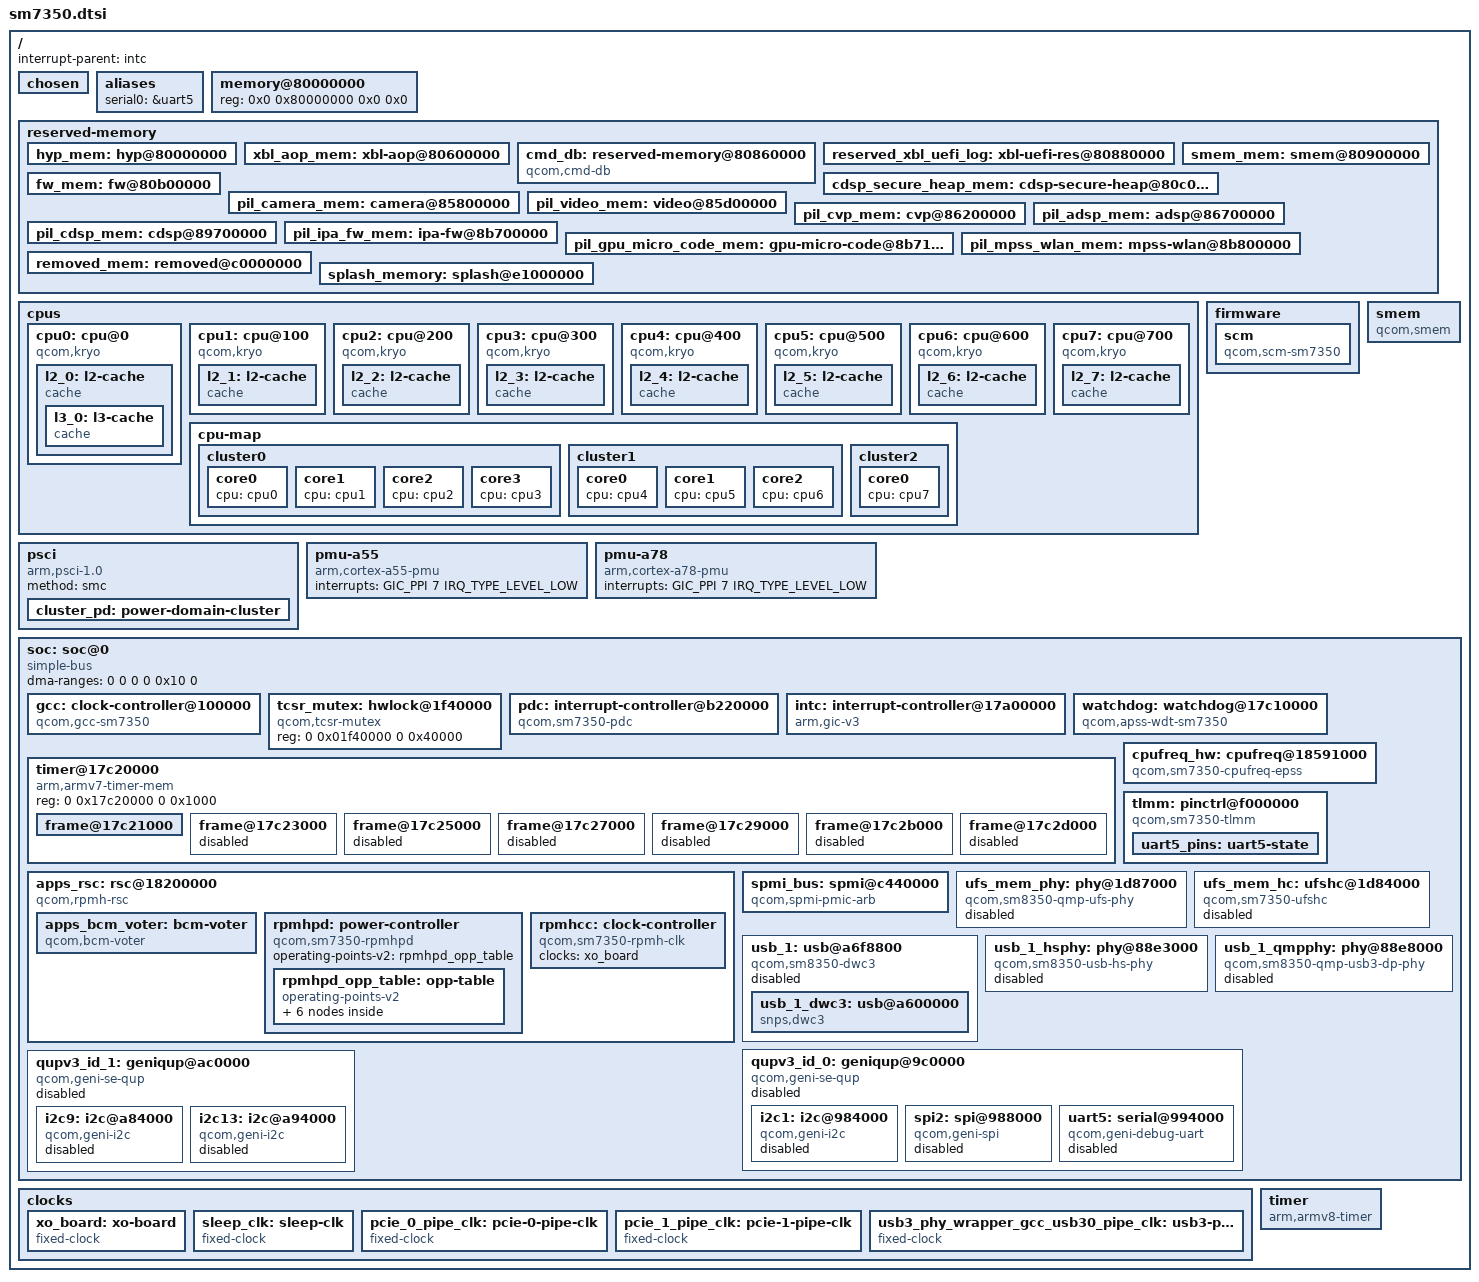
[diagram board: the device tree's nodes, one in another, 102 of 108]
// SPDX-License-Identifier: BSD-3-Clause
/*
 * Qualcomm SM7350 (Shima) SoC device tree
 *
 * Based on the downstream shima.dtsi and the mainline SM7325/Kodiak support.
 * Copyright (c) 2020-2021, The Linux Foundation. All rights reserved.
 * Copyright (c) 2026, Claude Agent <claude-agent@localhost>
 */

#include <dt-bindings/clock/qcom,gcc-sm7350.h>
#include <dt-bindings/clock/qcom,rpmh.h>
#include <dt-bindings/gpio/gpio.h>
#include <dt-bindings/interrupt-controller/arm-gic.h>
#include <dt-bindings/interrupt-controller/irq.h>
#include <dt-bindings/phy/phy-qcom-qmp.h>
#include <dt-bindings/power/qcom,rpmhpd.h>
#include <dt-bindings/soc/qcom,rpmh-rsc.h>
#include <dt-bindings/spmi/spmi.h>

/ {
	interrupt-parent = <&intc>;
	#address-cells = <2>;
	#size-cells = <2>;

	chosen { };

	aliases {
		serial0 = &uart5;
	};

	memory@80000000 {
		device_type = "memory";
		/* We expect the bootloader to fill in the size */
		reg = <0x0 0x80000000 0x0 0x0>;
	};

	reserved-memory {
		#address-cells = <2>;
		#size-cells = <2>;
		ranges;

		hyp_mem: hyp@80000000 {
			reg = <0x0 0x80000000 0x0 0x600000>;
			no-map;
		};

		xbl_aop_mem: xbl-aop@80600000 {
			reg = <0x0 0x80600000 0x0 0x260000>;
			no-map;
		};

		cmd_db: reserved-memory@80860000 {
			compatible = "qcom,cmd-db";
			reg = <0x0 0x80860000 0x0 0x20000>;
			no-map;
		};

		reserved_xbl_uefi_log: xbl-uefi-res@80880000 {
			reg = <0x0 0x80880000 0x0 0x14000>;
			no-map;
		};

		smem_mem: smem@80900000 {
			reg = <0x0 0x80900000 0x0 0x200000>;
			no-map;
		};

		fw_mem: fw@80b00000 {
			reg = <0x0 0x80b00000 0x0 0x100000>;
			no-map;
		};

		cdsp_secure_heap_mem: cdsp-secure-heap@80c00000 {
			reg = <0x0 0x80c00000 0x0 0x4600000>;
			no-map;
		};

		pil_camera_mem: camera@85800000 {
			reg = <0x0 0x85800000 0x0 0x500000>;
			no-map;
		};

		pil_video_mem: video@85d00000 {
			reg = <0x0 0x85d00000 0x0 0x500000>;
			no-map;
		};

		pil_cvp_mem: cvp@86200000 {
			reg = <0x0 0x86200000 0x0 0x500000>;
			no-map;
		};

		pil_adsp_mem: adsp@86700000 {
			reg = <0x0 0x86700000 0x0 0x3000000>;
			no-map;
		};

		pil_cdsp_mem: cdsp@89700000 {
			reg = <0x0 0x89700000 0x0 0x1e00000>;
			no-map;
		};

		pil_ipa_fw_mem: ipa-fw@8b700000 {
			reg = <0x0 0x8b700000 0x0 0x10000>;
			no-map;
		};

		pil_gpu_micro_code_mem: gpu-micro-code@8b71a000 {
			reg = <0x0 0x8b71a000 0x0 0x2000>;
			no-map;
		};

		pil_mpss_wlan_mem: mpss-wlan@8b800000 {
			reg = <0x0 0x8b800000 0x0 0x10000000>;
			no-map;
		};

		removed_mem: removed@c0000000 {
			reg = <0x0 0xc0000000 0x0 0x5100000>;
			no-map;
		};

		splash_memory: splash@e1000000 {
			reg = <0x0 0xe1000000 0x0 0x2300000>;
			no-map;
		};
	};

	cpus {
		#address-cells = <2>;
		#size-cells = <0>;

		cpu0: cpu@0 {
			device_type = "cpu";
			compatible = "qcom,kryo";
			reg = <0x0 0x0>;
			clocks = <&cpufreq_hw 0>;
			enable-method = "psci";
			next-level-cache = <&l2_0>;
			qcom,freq-domain = <&cpufreq_hw 0>;
			capacity-dmips-mhz = <1024>;
			dynamic-power-coefficient = <100>;
			#cooling-cells = <2>;

			l2_0: l2-cache {
				compatible = "cache";
				cache-level = <2>;
				cache-unified;
				next-level-cache = <&l3_0>;
				l3_0: l3-cache {
					compatible = "cache";
					cache-level = <3>;
					cache-unified;
				};
			};
		};

		cpu1: cpu@100 {
			device_type = "cpu";
			compatible = "qcom,kryo";
			reg = <0x0 0x100>;
			clocks = <&cpufreq_hw 0>;
			enable-method = "psci";
			next-level-cache = <&l2_1>;
			qcom,freq-domain = <&cpufreq_hw 0>;
			capacity-dmips-mhz = <1024>;
			dynamic-power-coefficient = <100>;
			#cooling-cells = <2>;

			l2_1: l2-cache {
				compatible = "cache";
				cache-level = <2>;
				cache-unified;
				next-level-cache = <&l3_0>;
			};
		};

		cpu2: cpu@200 {
			device_type = "cpu";
			compatible = "qcom,kryo";
			reg = <0x0 0x200>;
			clocks = <&cpufreq_hw 0>;
			enable-method = "psci";
			next-level-cache = <&l2_2>;
			qcom,freq-domain = <&cpufreq_hw 0>;
			capacity-dmips-mhz = <1024>;
			dynamic-power-coefficient = <100>;
			#cooling-cells = <2>;

			l2_2: l2-cache {
				compatible = "cache";
				cache-level = <2>;
				cache-unified;
				next-level-cache = <&l3_0>;
			};
		};

		cpu3: cpu@300 {
			device_type = "cpu";
			compatible = "qcom,kryo";
			reg = <0x0 0x300>;
			clocks = <&cpufreq_hw 0>;
			enable-method = "psci";
			next-level-cache = <&l2_3>;
			qcom,freq-domain = <&cpufreq_hw 0>;
			capacity-dmips-mhz = <1024>;
			dynamic-power-coefficient = <100>;
			#cooling-cells = <2>;

			l2_3: l2-cache {
				compatible = "cache";
				cache-level = <2>;
				cache-unified;
				next-level-cache = <&l3_0>;
			};
		};

		cpu4: cpu@400 {
			device_type = "cpu";
			compatible = "qcom,kryo";
			reg = <0x0 0x400>;
			clocks = <&cpufreq_hw 1>;
			enable-method = "psci";
			next-level-cache = <&l2_4>;
			qcom,freq-domain = <&cpufreq_hw 1>;
			capacity-dmips-mhz = <1946>;
			dynamic-power-coefficient = <520>;
			#cooling-cells = <2>;

			l2_4: l2-cache {
				compatible = "cache";
				cache-level = <2>;
				cache-unified;
				next-level-cache = <&l3_0>;
			};
		};

		cpu5: cpu@500 {
			device_type = "cpu";
			compatible = "qcom,kryo";
			reg = <0x0 0x500>;
			clocks = <&cpufreq_hw 1>;
			enable-method = "psci";
			next-level-cache = <&l2_5>;
			qcom,freq-domain = <&cpufreq_hw 1>;
			capacity-dmips-mhz = <1946>;
			dynamic-power-coefficient = <520>;
			#cooling-cells = <2>;

			l2_5: l2-cache {
				compatible = "cache";
				cache-level = <2>;
				cache-unified;
				next-level-cache = <&l3_0>;
			};
		};

		cpu6: cpu@600 {
			device_type = "cpu";
			compatible = "qcom,kryo";
			reg = <0x0 0x600>;
			clocks = <&cpufreq_hw 1>;
			enable-method = "psci";
			next-level-cache = <&l2_6>;
			qcom,freq-domain = <&cpufreq_hw 1>;
			capacity-dmips-mhz = <1946>;
			dynamic-power-coefficient = <520>;
			#cooling-cells = <2>;

			l2_6: l2-cache {
				compatible = "cache";
				cache-level = <2>;
				cache-unified;
				next-level-cache = <&l3_0>;
			};
		};

		cpu7: cpu@700 {
			device_type = "cpu";
			compatible = "qcom,kryo";
			reg = <0x0 0x700>;
			clocks = <&cpufreq_hw 2>;
			enable-method = "psci";
			next-level-cache = <&l2_7>;
			qcom,freq-domain = <&cpufreq_hw 2>;
			capacity-dmips-mhz = <1985>;
			dynamic-power-coefficient = <552>;
			#cooling-cells = <2>;

			l2_7: l2-cache {
				compatible = "cache";
				cache-level = <2>;
				cache-unified;
				next-level-cache = <&l3_0>;
			};
		};

		cpu-map {
			cluster0 {
				core0 { cpu = <&cpu0>; };
				core1 { cpu = <&cpu1>; };
				core2 { cpu = <&cpu2>; };
				core3 { cpu = <&cpu3>; };
			};

			cluster1 {
				core0 { cpu = <&cpu4>; };
				core1 { cpu = <&cpu5>; };
				core2 { cpu = <&cpu6>; };
			};

			cluster2 {
				core0 { cpu = <&cpu7>; };
			};
		};
	};

	psci {
		compatible = "arm,psci-1.0";
		method = "smc";

		cluster_pd: power-domain-cluster {
			#power-domain-cells = <0>;
		};
	};

	firmware {
		scm: scm {
			compatible = "qcom,scm-sm7350", "qcom,scm";
			#reset-cells = <1>;
		};
	};

	pmu-a55 {
		compatible = "arm,cortex-a55-pmu";
		interrupts = <GIC_PPI 7 IRQ_TYPE_LEVEL_LOW>;
	};

	pmu-a78 {
		compatible = "arm,cortex-a78-pmu";
		interrupts = <GIC_PPI 7 IRQ_TYPE_LEVEL_LOW>;
	};

	smem: smem {
		compatible = "qcom,smem";
		memory-region = <&smem_mem>;
		hwlocks = <&tcsr_mutex 3>;
	};

	soc: soc@0 {
		#address-cells = <2>;
		#size-cells = <2>;
		ranges = <0 0 0 0 0x10 0>;
		dma-ranges = <0 0 0 0 0x10 0>;
		compatible = "simple-bus";

		gcc: clock-controller@100000 {
			compatible = "qcom,gcc-sm7350";
			reg = <0 0x00100000 0 0x1f0000>;
			#clock-cells = <1>;
			#reset-cells = <1>;
			#power-domain-cells = <1>;

			clocks = <&rpmhcc RPMH_CXO_CLK>,
				 <&sleep_clk>,
				 <&pcie_0_pipe_clk>, <&pcie_1_pipe_clk>,
				 <&ufs_mem_phy 0>, <&ufs_mem_phy 1>, <&ufs_mem_phy 2>,
				 <&usb3_phy_wrapper_gcc_usb30_pipe_clk>;
			clock-names = "bi_tcxo", "sleep_clk",
				      "pcie_0_pipe_clk", "pcie_1_pipe_clk",
				      "ufs_phy_rx_symbol_0_clk", "ufs_phy_rx_symbol_1_clk",
				      "ufs_phy_tx_symbol_0_clk",
				      "usb3_phy_wrapper_gcc_usb30_pipe_clk";

			power-domains = <&rpmhpd SM7350_CX>;
		};

		tcsr_mutex: hwlock@1f40000 {
			compatible = "qcom,tcsr-mutex";
			reg = <0 0x01f40000 0 0x40000>;
			#hwlock-cells = <1>;
		};

		pdc: interrupt-controller@b220000 {
			compatible = "qcom,sm7350-pdc", "qcom,pdc";
			reg = <0 0x0b220000 0 0x30000>,
			      <0 0x17c000f0 0 0x64>;
			qcom,pdc-ranges = <0 480 40>, <40 140 14>, <54 263 1>,
					  <55 306 4>, <59 312 3>, <62 374 2>,
					  <64 434 2>, <66 438 3>, <69 86 1>,
					  <70 520 54>, <124 609 31>, <155 63 1>,
					  <156 716 12>;
			#interrupt-cells = <2>;
			interrupt-parent = <&intc>;
			interrupt-controller;
		};

		intc: interrupt-controller@17a00000 {
			compatible = "arm,gic-v3";
			reg = <0 0x17a00000 0 0x10000>,	/* GICD */
			      <0 0x17a60000 0 0x100000>;	/* GICR * 8 */
			interrupts = <GIC_PPI 9 IRQ_TYPE_LEVEL_LOW>;
			#interrupt-cells = <3>;
			interrupt-controller;
		};

		watchdog: watchdog@17c10000 {
			compatible = "qcom,apss-wdt-sm7350", "qcom,kpss-wdt";
			reg = <0 0x17c10000 0 0x1000>;
			clocks = <&sleep_clk>;
			interrupts = <GIC_SPI 0 IRQ_TYPE_EDGE_RISING>;
		};

		timer@17c20000 {
			#address-cells = <1>;
			#size-cells = <1>;
			ranges = <0 0 0 0x20000000>;
			compatible = "arm,armv7-timer-mem";
			reg = <0 0x17c20000 0 0x1000>;

			frame@17c21000 {
				frame-number = <0>;
				interrupts = <GIC_SPI 8 IRQ_TYPE_LEVEL_HIGH>,
					     <GIC_SPI 6 IRQ_TYPE_LEVEL_HIGH>;
				reg = <0x17c21000 0x1000>,
				      <0x17c22000 0x1000>;
			};

			frame@17c23000 {
				frame-number = <1>;
				interrupts = <GIC_SPI 9 IRQ_TYPE_LEVEL_HIGH>;
				reg = <0x17c23000 0x1000>;
				status = "disabled";
			};

			frame@17c25000 {
				frame-number = <2>;
				interrupts = <GIC_SPI 10 IRQ_TYPE_LEVEL_HIGH>;
				reg = <0x17c25000 0x1000>;
				status = "disabled";
			};

			frame@17c27000 {
				frame-number = <3>;
				interrupts = <GIC_SPI 11 IRQ_TYPE_LEVEL_HIGH>;
				reg = <0x17c27000 0x1000>;
				status = "disabled";
			};

			frame@17c29000 {
				frame-number = <4>;
				interrupts = <GIC_SPI 12 IRQ_TYPE_LEVEL_HIGH>;
				reg = <0x17c29000 0x1000>;
				status = "disabled";
			};

			frame@17c2b000 {
				frame-number = <5>;
				interrupts = <GIC_SPI 13 IRQ_TYPE_LEVEL_HIGH>;
				reg = <0x17c2b000 0x1000>;
				status = "disabled";
			};

			frame@17c2d000 {
				frame-number = <6>;
				interrupts = <GIC_SPI 14 IRQ_TYPE_LEVEL_HIGH>;
				reg = <0x17c2d000 0x1000>;
				status = "disabled";
			};
		};

		apps_rsc: rsc@18200000 {
			compatible = "qcom,rpmh-rsc";
			reg = <0 0x18200000 0 0x10000>,
			      <0 0x18210000 0 0x10000>,
			      <0 0x18220000 0 0x10000>;
			reg-names = "drv-0", "drv-1", "drv-2";
			interrupts = <GIC_SPI 3 IRQ_TYPE_LEVEL_HIGH>,
				     <GIC_SPI 4 IRQ_TYPE_LEVEL_HIGH>,
				     <GIC_SPI 5 IRQ_TYPE_LEVEL_HIGH>;
			power-domains = <&cluster_pd>;
			qcom,tcs-offset = <0xd00>;
			qcom,drv-id = <2>;
			qcom,tcs-config = <ACTIVE_TCS 2>,
					  <SLEEP_TCS 3>,
					  <WAKE_TCS 3>,
					  <CONTROL_TCS 0>;

			apps_bcm_voter: bcm-voter {
				compatible = "qcom,bcm-voter";
			};

			rpmhpd: power-controller {
				compatible = "qcom,sm7350-rpmhpd";
				#power-domain-cells = <1>;
				operating-points-v2 = <&rpmhpd_opp_table>;

				rpmhpd_opp_table: opp-table {
					compatible = "operating-points-v2";

					rpmhpd_opp_ret: opp1 {
						opp-level = <RPMH_REGULATOR_LEVEL_RETENTION>;
					};

					rpmhpd_opp_low_svs: opp2 {
						opp-level = <RPMH_REGULATOR_LEVEL_LOW_SVS>;
					};

					rpmhpd_opp_svs: opp3 {
						opp-level = <RPMH_REGULATOR_LEVEL_SVS>;
					};

					rpmhpd_opp_svs_l1: opp4 {
						opp-level = <RPMH_REGULATOR_LEVEL_SVS_L1>;
					};

					rpmhpd_opp_nom: opp5 {
						opp-level = <RPMH_REGULATOR_LEVEL_NOM>;
					};

					rpmhpd_opp_turbo: opp6 {
						opp-level = <RPMH_REGULATOR_LEVEL_TURBO>;
					};
				};
			};

			rpmhcc: clock-controller {
				compatible = "qcom,sm7350-rpmh-clk";
				clocks = <&xo_board>;
				clock-names = "xo";
				#clock-cells = <1>;
			};
		};

		cpufreq_hw: cpufreq@18591000 {
			compatible = "qcom,sm7350-cpufreq-epss", "qcom,cpufreq-epss";
			reg = <0 0x18591000 0 0x1000>,
			      <0 0x18592000 0 0x1000>,
			      <0 0x18593000 0 0x1000>;
			interrupts = <GIC_SPI 30 IRQ_TYPE_LEVEL_HIGH>,
				     <GIC_SPI 31 IRQ_TYPE_LEVEL_HIGH>,
				     <GIC_SPI 19 IRQ_TYPE_LEVEL_HIGH>;
			interrupt-names = "dcvsh-irq-0", "dcvsh-irq-1", "dcvsh-irq-2";
			clocks = <&rpmhcc RPMH_CXO_CLK>, <&gcc GCC_GPLL0>;
			clock-names = "xo", "alternate";
			#clock-cells = <1>;
			#freq-domain-cells = <1>;
		};

		tlmm: pinctrl@f000000 {
			compatible = "qcom,sm7350-tlmm";
			reg = <0 0x0f000000 0 0x1000000>;
			interrupts = <GIC_SPI 208 IRQ_TYPE_LEVEL_HIGH>;
			gpio-controller;
			#gpio-cells = <2>;
			interrupt-controller;
			#interrupt-cells = <2>;
			gpio-ranges = <&tlmm 0 0 205>;
			wakeup-parent = <&pdc>;

			uart5_pins: uart5-state {
				pins = "gpio18", "gpio19";
				function = "qup13";
				drive-strength = <2>;
				bias-disable;
			};
		};

		spmi_bus: spmi@c440000 {
			compatible = "qcom,spmi-pmic-arb";
			reg = <0 0x0c440000 0 0x1100>,
			      <0 0x0c600000 0 0x2000000>,
			      <0 0x0e600000 0 0x100000>,
			      <0 0x0e700000 0 0xa0000>,
			      <0 0x0c40a000 0 0x26000>;
			reg-names = "core", "chnls", "obsrvr", "intr", "cnfg";
			interrupt-names = "periph_irq";
			interrupts-extended = <&pdc 1 IRQ_TYPE_LEVEL_HIGH>;
			qcom,ee = <0>;
			qcom,channel = <0>;
			#address-cells = <2>;
			#size-cells = <0>;
			interrupt-controller;
			#interrupt-cells = <4>;
		};

		ufs_mem_phy: phy@1d87000 {
			compatible = "qcom,sm8350-qmp-ufs-phy";
			reg = <0 0x01d87000 0 0x1000>;
			clocks = <&rpmhcc RPMH_CXO_CLK>,
				 <&gcc GCC_UFS_PHY_PHY_AUX_CLK>,
				 <&gcc GCC_UFS_1_CLKREF_EN>;
			clock-names = "ref", "ref_aux", "qref";
			power-domains = <&gcc GCC_UFS_PHY_GDSC>;
			resets = <&ufs_mem_hc 0>;
			reset-names = "ufsphy";
			#clock-cells = <1>;
			#phy-cells = <0>;
			status = "disabled";
		};

		ufs_mem_hc: ufshc@1d84000 {
			compatible = "qcom,sm7350-ufshc", "qcom,ufshc",
				     "jedec,ufs-2.0";
			reg = <0 0x01d84000 0 0x3000>;
			interrupts = <GIC_SPI 265 IRQ_TYPE_LEVEL_HIGH>;
			phys = <&ufs_mem_phy>;
			phy-names = "ufsphy";
			lanes-per-direction = <2>;
			#reset-cells = <1>;
			resets = <&gcc GCC_UFS_PHY_BCR>;
			reset-names = "rst";

			power-domains = <&gcc GCC_UFS_PHY_GDSC>;

			clocks = <&gcc GCC_UFS_PHY_AXI_CLK>,
				 <&gcc GCC_AGGRE_UFS_PHY_AXI_CLK>,
				 <&gcc GCC_UFS_PHY_AHB_CLK>,
				 <&gcc GCC_UFS_PHY_UNIPRO_CORE_CLK>,
				 <&gcc GCC_UFS_PHY_ICE_CORE_CLK>,
				 <&rpmhcc RPMH_CXO_CLK>,
				 <&gcc GCC_UFS_PHY_TX_SYMBOL_0_CLK>,
				 <&gcc GCC_UFS_PHY_RX_SYMBOL_0_CLK>,
				 <&gcc GCC_UFS_PHY_RX_SYMBOL_1_CLK>;
			clock-names = "core_clk", "bus_aggr_clk", "iface_clk",
				      "core_clk_unipro", "core_clk_ice", "ref_clk",
				      "tx_lane0_sync_clk", "rx_lane0_sync_clk",
				      "rx_lane1_sync_clk";
			freq-table-hz = <75000000 300000000>,
					<0 0>,
					<0 0>,
					<75000000 300000000>,
					<75000000 300000000>,
					<0 0>,
					<0 0>,
					<0 0>,
					<0 0>;

			status = "disabled";
		};

		usb_1: usb@a6f8800 {
			compatible = "qcom,sm8350-dwc3", "qcom,dwc3";
			reg = <0 0x0a6f8800 0 0x400>;
			#address-cells = <2>;
			#size-cells = <2>;
			ranges;
			status = "disabled";

			clocks = <&gcc GCC_CFG_NOC_USB3_PRIM_AXI_CLK>,
				 <&gcc GCC_USB30_PRIM_MASTER_CLK>,
				 <&gcc GCC_AGGRE_USB3_PRIM_AXI_CLK>,
				 <&gcc GCC_USB30_PRIM_SLEEP_CLK>,
				 <&gcc GCC_USB30_PRIM_MOCK_UTMI_CLK>;
			clock-names = "cfg_noc", "core", "iface", "sleep", "mock_utmi";

			assigned-clocks = <&gcc GCC_USB30_PRIM_MOCK_UTMI_CLK>,
					  <&gcc GCC_USB30_PRIM_MASTER_CLK>;
			assigned-clock-rates = <19200000>, <200000000>;

			interrupts-extended = <&intc GIC_SPI 130 IRQ_TYPE_LEVEL_HIGH>,
					      <&intc GIC_SPI 131 IRQ_TYPE_LEVEL_HIGH>,
					      <&pdc 14 IRQ_TYPE_EDGE_BOTH>,
					      <&pdc 15 IRQ_TYPE_EDGE_BOTH>,
					      <&pdc 17 IRQ_TYPE_LEVEL_HIGH>;
			interrupt-names = "pwr_event", "hs_phy_irq",
					  "dp_hs_phy_irq", "dm_hs_phy_irq",
					  "ss_phy_irq";

			power-domains = <&gcc GCC_USB30_PRIM_GDSC>;
			resets = <&gcc GCC_USB30_PRIM_BCR>;

			usb_1_dwc3: usb@a600000 {
				compatible = "snps,dwc3";
				reg = <0 0x0a600000 0 0xcd00>;
				interrupts = <GIC_SPI 133 IRQ_TYPE_LEVEL_HIGH>;
				phys = <&usb_1_hsphy>, <&usb_1_qmpphy QMP_USB43DP_USB3_PHY>;
				phy-names = "usb2-phy", "usb3-phy";
				snps,dis_u2_susphy_quirk;
				snps,dis_enblslpm_quirk;
				snps,parkmode-disable-ss-quirk;
			};
		};

		usb_1_hsphy: phy@88e3000 {
			compatible = "qcom,sm8350-usb-hs-phy", "qcom,usb-snps-hs-7nm-phy";
			reg = <0 0x088e3000 0 0x1c0>;
			clocks = <&rpmhcc RPMH_CXO_CLK>;
			clock-names = "ref";
			resets = <&gcc GCC_QUSB2PHY_PRIM_BCR>;
			#phy-cells = <0>;
			status = "disabled";
		};

		usb_1_qmpphy: phy@88e8000 {
			compatible = "qcom,sm8350-qmp-usb3-dp-phy";
			reg = <0 0x088e8000 0 0x3000>;
			clocks = <&gcc GCC_USB3_PRIM_PHY_AUX_CLK>,
				 <&rpmhcc RPMH_CXO_CLK>,
				 <&gcc GCC_USB3_PRIM_PHY_COM_AUX_CLK>,
				 <&gcc GCC_USB3_PRIM_PHY_PIPE_CLK>;
			clock-names = "aux", "ref", "com_aux", "usb3_pipe";
			resets = <&gcc GCC_USB3_DP_PHY_PRIM_BCR>,
				 <&gcc GCC_USB3_PHY_PRIM_BCR>;
			reset-names = "phy", "common";
			#clock-cells = <1>;
			#phy-cells = <1>;
			status = "disabled";
		};

		qupv3_id_0: geniqup@9c0000 {
			compatible = "qcom,geni-se-qup";
			reg = <0 0x009c0000 0 0x2000>;
			clocks = <&gcc GCC_QUPV3_WRAP_0_M_AHB_CLK>,
				 <&gcc GCC_QUPV3_WRAP_0_S_AHB_CLK>;
			clock-names = "m-ahb", "s-ahb";
			#address-cells = <2>;
			#size-cells = <2>;
			ranges;
			status = "disabled";

			i2c1: i2c@984000 {
				compatible = "qcom,geni-i2c";
				reg = <0 0x00984000 0 0x4000>;
				clocks = <&gcc GCC_QUPV3_WRAP0_S1_CLK>;
				clock-names = "se";
				interrupts = <GIC_SPI 602 IRQ_TYPE_LEVEL_HIGH>;
				#address-cells = <1>;
				#size-cells = <0>;
				status = "disabled";
			};

			spi2: spi@988000 {
				compatible = "qcom,geni-spi";
				reg = <0 0x00988000 0 0x4000>;
				clocks = <&gcc GCC_QUPV3_WRAP0_S2_CLK>;
				clock-names = "se";
				interrupts = <GIC_SPI 603 IRQ_TYPE_LEVEL_HIGH>;
				#address-cells = <1>;
				#size-cells = <0>;
				status = "disabled";
			};

			uart5: serial@994000 {
				compatible = "qcom,geni-debug-uart";
				reg = <0 0x00994000 0 0x4000>;
				clocks = <&gcc GCC_QUPV3_WRAP0_S5_CLK>;
				clock-names = "se";
				interrupts = <GIC_SPI 606 IRQ_TYPE_LEVEL_HIGH>;
				pinctrl-0 = <&uart5_pins>;
				pinctrl-names = "default";
				status = "disabled";
			};
		};

		qupv3_id_1: geniqup@ac0000 {
			compatible = "qcom,geni-se-qup";
			reg = <0 0x00ac0000 0 0x2000>;
			clocks = <&gcc GCC_QUPV3_WRAP_1_M_AHB_CLK>,
				 <&gcc GCC_QUPV3_WRAP_1_S_AHB_CLK>;
			clock-names = "m-ahb", "s-ahb";
			#address-cells = <2>;
			#size-cells = <2>;
			ranges;
			status = "disabled";

			i2c9: i2c@a84000 {
				compatible = "qcom,geni-i2c";
				reg = <0 0x00a84000 0 0x4000>;
				clocks = <&gcc GCC_QUPV3_WRAP1_S1_CLK>;
				clock-names = "se";
				interrupts = <GIC_SPI 609 IRQ_TYPE_LEVEL_HIGH>;
				#address-cells = <1>;
				#size-cells = <0>;
				status = "disabled";
			};

			i2c13: i2c@a94000 {
				compatible = "qcom,geni-i2c";
				reg = <0 0x00a94000 0 0x4000>;
				clocks = <&gcc GCC_QUPV3_WRAP1_S5_CLK>;
				clock-names = "se";
				interrupts = <GIC_SPI 613 IRQ_TYPE_LEVEL_HIGH>;
				#address-cells = <1>;
				#size-cells = <0>;
				status = "disabled";
			};
		};
	};

	clocks {
		xo_board: xo-board {
			compatible = "fixed-clock";
			clock-frequency = <38400000>;
			clock-output-names = "xo_board";
			#clock-cells = <0>;
		};

		sleep_clk: sleep-clk {
			compatible = "fixed-clock";
			clock-frequency = <32000>;
			clock-output-names = "sleep_clk";
			#clock-cells = <0>;
		};

		pcie_0_pipe_clk: pcie-0-pipe-clk {
			compatible = "fixed-clock";
			clock-frequency = <1000>;
			clock-output-names = "pcie_0_pipe_clk";
			#clock-cells = <0>;
		};

		pcie_1_pipe_clk: pcie-1-pipe-clk {
			compatible = "fixed-clock";
			clock-frequency = <1000>;
			clock-output-names = "pcie_1_pipe_clk";
			#clock-cells = <0>;
		};

		usb3_phy_wrapper_gcc_usb30_pipe_clk: usb3-phy-wrapper-gcc-usb30-pipe-clk {
			compatible = "fixed-clock";
			clock-frequency = <1000>;
			clock-output-names = "usb3_phy_wrapper_gcc_usb30_pipe_clk";
			#clock-cells = <0>;
		};
	};

	timer {
		compatible = "arm,armv8-timer";
		interrupts = <GIC_PPI 13 IRQ_TYPE_LEVEL_LOW>,
			     <GIC_PPI 14 IRQ_TYPE_LEVEL_LOW>,
			     <GIC_PPI 11 IRQ_TYPE_LEVEL_LOW>,
			     <GIC_PPI 10 IRQ_TYPE_LEVEL_LOW>;
	};
};
